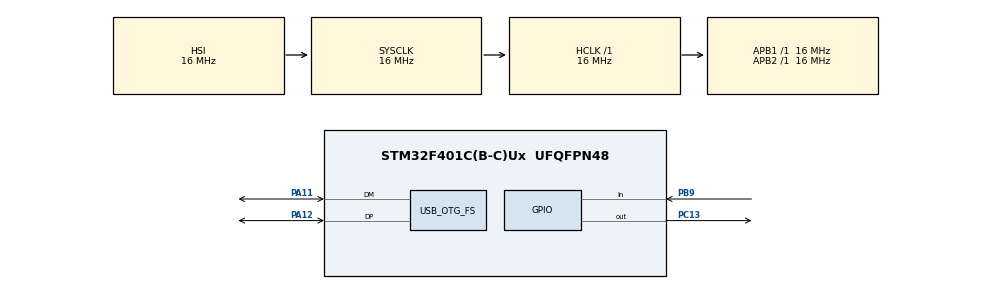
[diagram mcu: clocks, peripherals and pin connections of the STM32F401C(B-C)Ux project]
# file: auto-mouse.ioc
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Mcu.Family=STM32F4
Mcu.Name=STM32F401C(B-C)Ux
Mcu.Package=UFQFPN48
NVIC.OTG_FS_IRQn=true\:0\:0\:false\:false\:true\:false\:true\:true
NVIC.PriorityGroup=NVIC_PRIORITYGROUP_4
PA11.Mode=Device_Only
PA11.Signal=USB_OTG_FS_DM
PA12.Mode=Device_Only
PA12.Signal=USB_OTG_FS_DP
PB9.GPIO_PuPd=GPIO_PULLUP
PB9.Signal=GPIO_Input
PC13-ANTI_TAMP.GPIO_ModeDefaultOutputPP=GPIO_MODE_OUTPUT_OD
PC13-ANTI_TAMP.GPIO_PuPd=GPIO_NOPULL
PC13-ANTI_TAMP.Signal=GPIO_Output
PC14-OSC32_IN.Mode=LSE-External-Oscillator
PC14-OSC32_IN.Signal=RCC_OSC32_IN
PC15-OSC32_OUT.Mode=LSE-External-Oscillator
PC15-OSC32_OUT.Signal=RCC_OSC32_OUT
PH0\ -\ OSC_IN.Mode=HSE-External-Oscillator
PH0\ -\ OSC_IN.Signal=RCC_OSC_IN
PH1\ -\ OSC_OUT.Mode=HSE-External-Oscillator
PH1\ -\ OSC_OUT.Signal=RCC_OSC_OUT
ProjectManager.HeapSize=0x1000
ProjectManager.StackSize=0x1000
ProjectManager.TargetToolchain=Makefile
RCC.48MHZClocksFreq_Value=48000000
RCC.AHBFreq_Value=16000000
RCC.APB1Freq_Value=16000000
RCC.APB2Freq_Value=16000000
RCC.CortexFreq_Value=16000000
RCC.HSE_VALUE=25000000
RCC.HSI_VALUE=16000000
RCC.PLLM=15
RCC.PLLN=144
RCC.PLLQ=5
RCC.SYSCLKFreq_VALUE=16000000
RCC.VCOOutputFreq_Value=240000000
USB_DEVICE.CLASS_NAME_FS=HID
USB_DEVICE.HID_FS_BINTERVAL=0x1
USB_DEVICE.USBD_MAX_NUM_INTERFACES=3
USB_DEVICE.VirtualMode=Hid
USB_DEVICE.VirtualModeFS=Hid_FS
USB_OTG_FS.VirtualMode=Device_Only
VP_USB_DEVICE_VS_USB_DEVICE_HID_FS.Mode=HID_FS
board=custom

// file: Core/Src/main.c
/* USER CODE BEGIN Header */
/**
 ******************************************************************************
 * @file           : main.c
 * @brief          : Main program body
 ******************************************************************************
 * @attention
 *
 * <h2><center>&copy; Copyright (c) 2021 STMicroelectronics.
 * All rights reserved.</center></h2>
 *
 * This software component is licensed by ST under Ultimate Liberty license
 * SLA0044, the "License"; You may not use this file except in compliance with
 * the License. You may obtain a copy of the License at:
 *                             www.st.com/SLA0044
 *
 ******************************************************************************
 */
/* USER CODE END Header */
#include "main.h"
#include "usb_device.h"

/* USER CODE BEGIN Includes */
#include "usbd_hid.h"
/* USER CODE END Includes */

void SystemClock_Config(void);
static void MX_GPIO_Init(void);

/* USER CODE BEGIN 0 */
uint8_t kbData[8];
/* USER CODE END 0 */

int main(void)
{

  /* MCU Configuration--------------------------------------------------------*/

  /* Reset of all peripherals, Initializes the Flash interface and the Systick. */
  HAL_Init();

  /* Configure the system clock */
  SystemClock_Config();

  /* Initialize all configured peripherals */
  MX_GPIO_Init();
  MX_USB_DEVICE_Init();
  /* USER CODE BEGIN 2 */
  HAL_GPIO_WritePin(GPIOC, GPIO_PIN_13, GPIO_PIN_SET);
  /* USER CODE END 2 */

  /* Infinite loop */
  while (1)
  {

    if (!HAL_GPIO_ReadPin(GPIOB, GPIO_PIN_9))
    {
      if (!kbData[0])
      {
        kbData[0] = 1; // ctrl
        USBD_HID_SendReport(USB_getDevFs(), HID_KB_EPIN_ADDR, kbData, HID_KB_EPIN_SIZE);
      }
    }
    else
    {
      if (kbData[0])
      {
        kbData[0] = 0; // release ctrl
        USBD_HID_SendReport(USB_getDevFs(), HID_KB_EPIN_ADDR, kbData, HID_KB_EPIN_SIZE);
      }
    }
  }
}

void SystemClock_Config(void)
{
  RCC_OscInitTypeDef RCC_OscInitStruct = {0};
  RCC_ClkInitTypeDef RCC_ClkInitStruct = {0};

  /** Configure the main internal regulator output voltage
   */
  __HAL_RCC_PWR_CLK_ENABLE();
  __HAL_PWR_VOLTAGESCALING_CONFIG(PWR_REGULATOR_VOLTAGE_SCALE2);
  /** Initializes the RCC Oscillators according to the specified parameters
   * in the RCC_OscInitTypeDef structure.
   */
  RCC_OscInitStruct.OscillatorType = RCC_OSCILLATORTYPE_HSI | RCC_OSCILLATORTYPE_HSE;
  RCC_OscInitStruct.HSEState = RCC_HSE_ON;
  RCC_OscInitStruct.HSIState = RCC_HSI_ON;
  RCC_OscInitStruct.HSICalibrationValue = RCC_HSICALIBRATION_DEFAULT;
  RCC_OscInitStruct.PLL.PLLState = RCC_PLL_ON;
  RCC_OscInitStruct.PLL.PLLSource = RCC_PLLSOURCE_HSE;
  RCC_OscInitStruct.PLL.PLLM = 15;
  RCC_OscInitStruct.PLL.PLLN = 144;
  RCC_OscInitStruct.PLL.PLLP = RCC_PLLP_DIV2;
  RCC_OscInitStruct.PLL.PLLQ = 5;
  if (HAL_RCC_OscConfig(&RCC_OscInitStruct) != HAL_OK)
  {
    Error_Handler();
  }
  /** Initializes the CPU, AHB and APB buses clocks
   */
  RCC_ClkInitStruct.ClockType = RCC_CLOCKTYPE_HCLK | RCC_CLOCKTYPE_SYSCLK | RCC_CLOCKTYPE_PCLK1 | RCC_CLOCKTYPE_PCLK2;
  RCC_ClkInitStruct.SYSCLKSource = RCC_SYSCLKSOURCE_HSI;
  RCC_ClkInitStruct.AHBCLKDivider = RCC_SYSCLK_DIV1;
  RCC_ClkInitStruct.APB1CLKDivider = RCC_HCLK_DIV1;
  RCC_ClkInitStruct.APB2CLKDivider = RCC_HCLK_DIV1;

  if (HAL_RCC_ClockConfig(&RCC_ClkInitStruct, FLASH_LATENCY_0) != HAL_OK)
  {
    Error_Handler();
  }
}

static void MX_GPIO_Init(void)
{
  GPIO_InitTypeDef GPIO_InitStruct = {0};

  /* GPIO Ports Clock Enable */
  __HAL_RCC_GPIOC_CLK_ENABLE();
  __HAL_RCC_GPIOH_CLK_ENABLE();
  __HAL_RCC_GPIOA_CLK_ENABLE();
  __HAL_RCC_GPIOB_CLK_ENABLE();

  /*Configure GPIO pin Output Level */
  HAL_GPIO_WritePin(GPIOC, GPIO_PIN_13, GPIO_PIN_RESET);

  /*Configure GPIO pin : PC13 */
  GPIO_InitStruct.Pin = GPIO_PIN_13;
  GPIO_InitStruct.Mode = GPIO_MODE_OUTPUT_OD;
  GPIO_InitStruct.Pull = GPIO_NOPULL;
  GPIO_InitStruct.Speed = GPIO_SPEED_FREQ_LOW;
  HAL_GPIO_Init(GPIOC, &GPIO_InitStruct);

  /*Configure GPIO pin : PB9 */
  GPIO_InitStruct.Pin = GPIO_PIN_9;
  GPIO_InitStruct.Mode = GPIO_MODE_INPUT;
  GPIO_InitStruct.Pull = GPIO_PULLUP;
  HAL_GPIO_Init(GPIOB, &GPIO_InitStruct);
}

void Error_Handler(void)
{
  __disable_irq();
  while (1)
  {
  }
}

/************************ (C) COPYRIGHT STMicroelectronics *****END OF FILE****/
